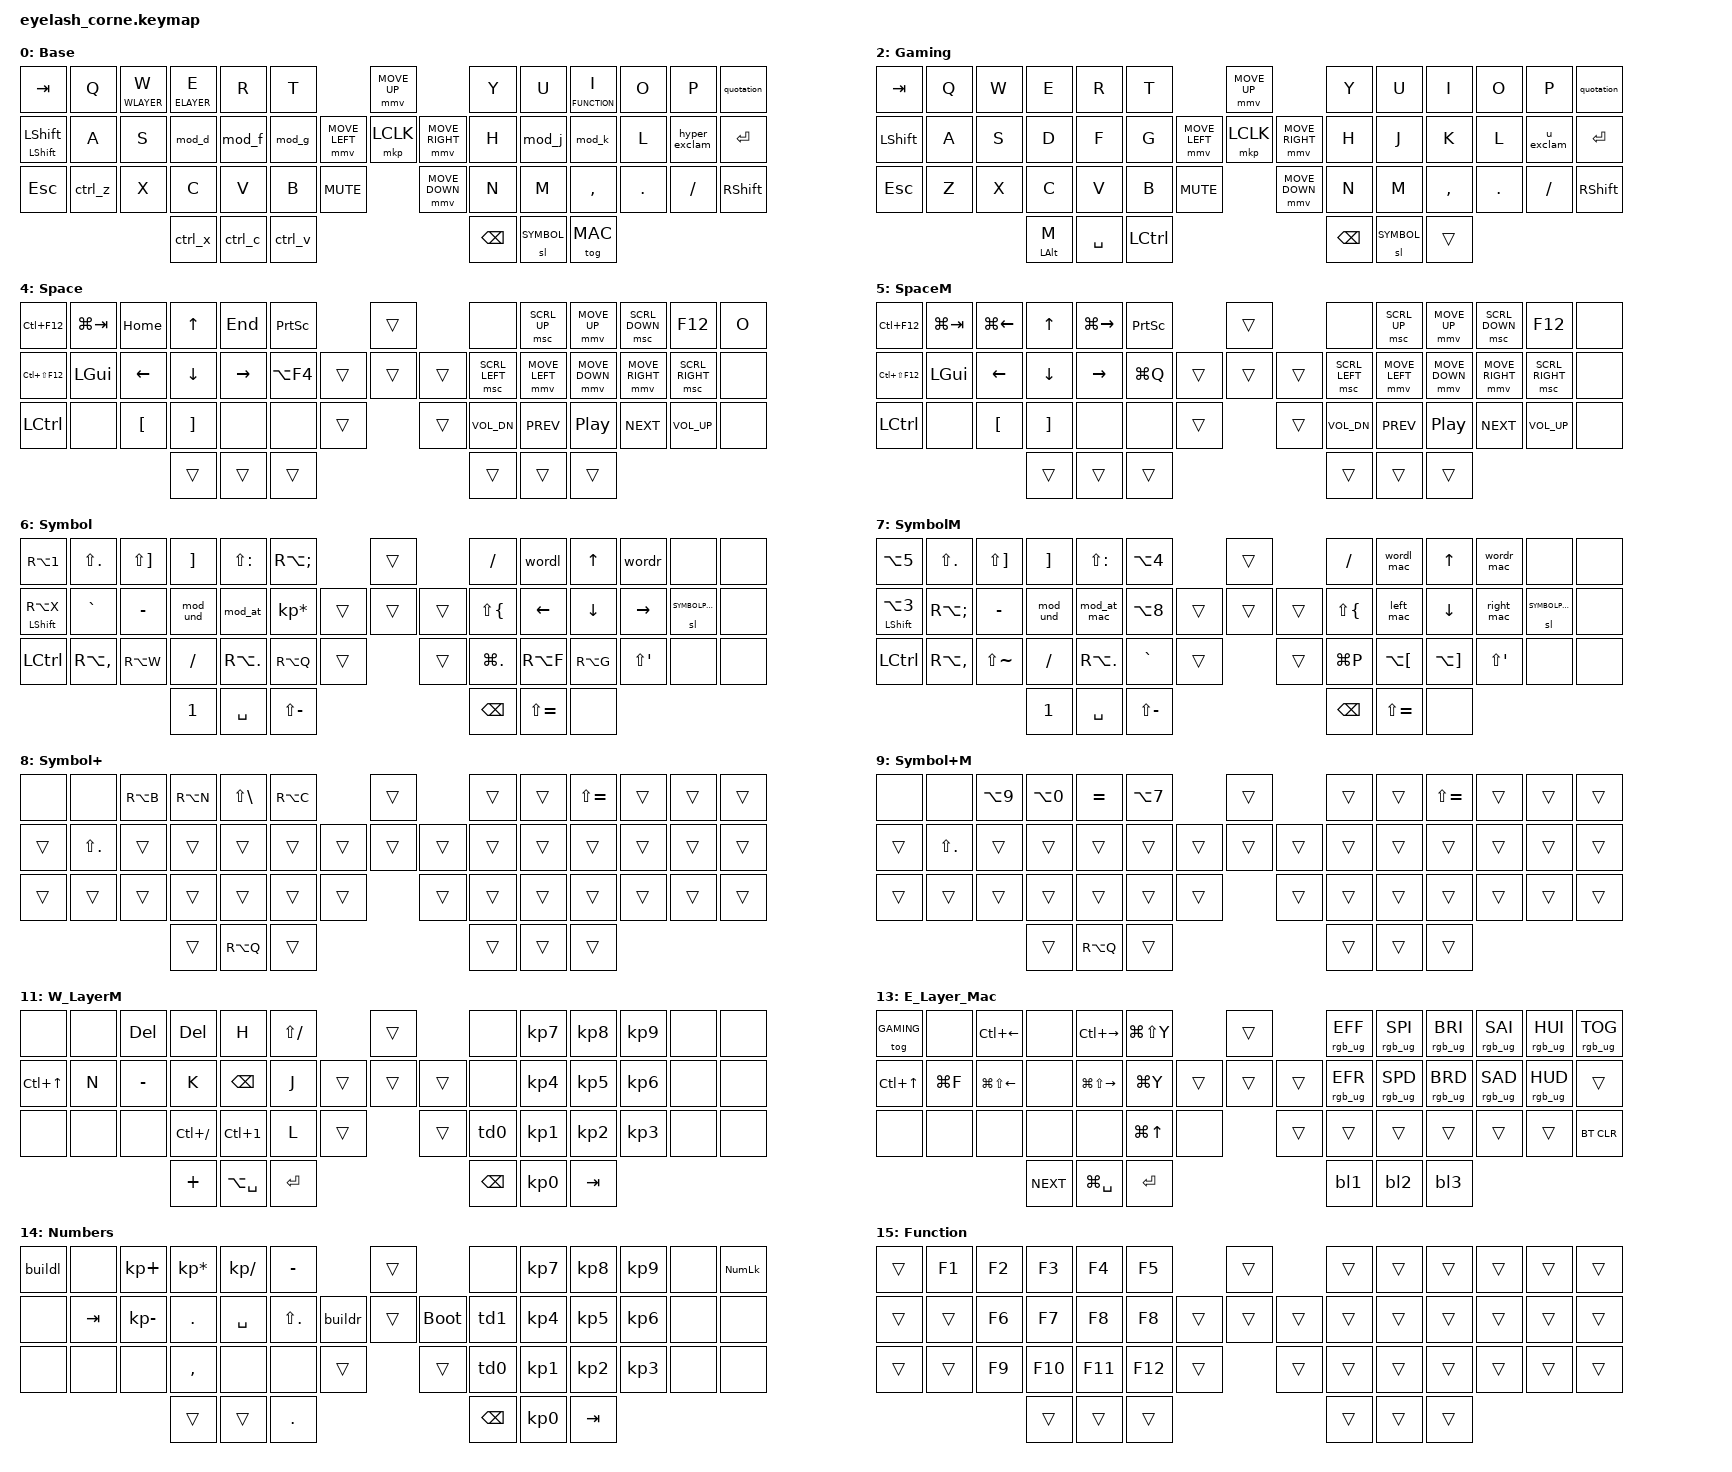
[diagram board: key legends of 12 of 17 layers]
#define ZMK_POINTING_DEFAULT_MOVE_VAL 1200  // 600
#define ZMK_POINTING_DEFAULT_SCRL_VAL 25   // 10

#include <input/processors.dtsi>
#include <zephyr/dt-bindings/input/input-event-codes.h>
#include <behaviors.dtsi>
#include <dt-bindings/zmk/bt.h>
#include <dt-bindings/zmk/keys.h>
#include <dt-bindings/zmk/outputs.h>
#include <dt-bindings/zmk/pointing.h>
#include <dt-bindings/zmk/rgb.h>

#define BASE 0
#define MAC 1
#define GAMING 2
#define GAMINGMAC 3
#define SPACELAYER 4
#define SPACELAYERMAC 5
#define SYMBOL 6
#define SYMBOLMAC 7
#define SYMBOLPLUS 8
#define SYMBOLPLUSMAC 9
#define WLAYER 10
#define WLAYERMAC 11
#define ELAYER 12
#define ELAYERMAC 13
#define NUMBERS 14
#define FUNCTION 15

// -------------------------------------------------------------------------------------------------------------------------------------------------------------------------------------------------------------------------------------------------------------------------------------------------------------------

// Caps Word
&caps_word {
    continue-list = <UNDERSCORE MINUS LS(SLASH) BACKSPACE>;
};

// Layer Tap
&lt {
    quick-tap-ms = <200>;
    tapping-term-ms = <200>;
};

// Sticky key
&sk {
    release-after-ms = <2000>;
    quick-release;
    /delete-property/ ignore-modifiers;
};

// Mouse Movement
&mmv {
    x-input-code = <INPUT_REL_X>;
    y-input-code = <INPUT_REL_Y>;
    time-to-max-speed-ms = <200>;
    acceleration-exponent = <1>;
};

// Mouse Scroll
&msc {
    x-input-code = <INPUT_REL_HWHEEL>;
    y-input-code = <INPUT_REL_WHEEL>;
    time-to-max-speed-ms = <1000>;
    acceleration-exponent = <2>;
};

// -------------------------------------------------------------------------------------------------------------------------------------------------------------------------------------------------------------------------------------------------------------------------------------------------------------------

//tab 0,    q 1,    w 2,   e 3,    r 4,    t 5,    y 7,    u 8,    i 9,    o 10,    p 11,   ' 12
//shift 13, a 14,   s 15,  d 16,   f 17,   g 18,   h 22,   j 23,   k 24,   l 25,   ; 26,   enter 27
//esc 28,   z 29,   x 30,  c 31,   v 32,   b 33,   n 36,   m 37,   , 38,   . 39,   / 40,   shift 40
//                                 42 43 44,           45 46 47

/ {
    combos {
        compatible = "zmk,combos";
        combo_rename {
            timeout-ms = <50>;
            key-positions = <1 2>;
            bindings = <&kp F2>;
        };

        combo_f5 {
            timeout-ms = <50>;
            key-positions = <3 15 17>;
            bindings = <&kp F5>;
            layers = <0 1 3 4 5 6>;  
        };

        combo_we {
            timeout-ms = <30>;
            key-positions = <2 3>;
            bindings = <&kp ESC>;
            layers = <0 1>; 
        };

        combo_lock {
            timeout-ms = <50>;
            key-positions = <11 12>;
            bindings = <&kp LG(L)>;
            layers = <0>; 
        };

        combo_lock_mac {
            timeout-ms = <50>;
            key-positions = <11 12>;
            bindings = <&kp LG(BSLH)>;
            layers = <1>; 
        }; 

        combo_sound {
            timeout-ms = <10>;
            key-positions = <14 18>;
            bindings = <&kp LG(A)>;
        };

        combo_m {
            timeout-ms = <10>;
            key-positions = <3 4>;
            bindings = <&kp M>;
            layers = <0 1>;  
        };

       combo_win_e {
            timeout-ms = <30>;
            key-positions = <3 44>;
            bindings = <&kp LG(E)>;
            layers = <0>;  
        };

       combo_finder {
            timeout-ms = <30>;
            key-positions = <3 44>;
            bindings = <&kp LA(LG(SPACE))>;
            layers = <1>;  
        };

       combo_gaming {
            timeout-ms = <30>;
            key-positions = <0 1>;
            bindings = <&tog GAMING>;
            layers = <0 1 2>;  
        };

       combo_mac {
            timeout-ms = <30>;
            key-positions = <0 13>;
            bindings = <&tog MAC>;
            layers = <0 1 2>;  
        };

    };
};

// -------------------------------------------------------------------------------------------------------------------------------------------------------------------------------------------------------------------------------------------------------------------------------------------------------------------

/ {
    macros {
        m_speed1: m_speed1 {
            compatible = "zmk,behavior-macro";
            #binding-cells = <0>;
            wait-ms = <200>;
            tap-ms = <20>;
            bindings
                = <&macro_tap &kp LS(R)>
                ,<&macro_wait_time 20>
                ,<&macro_tap &kp KP_N2 &kp KP_N0 &kp KP_N0>
                ,<&macro_wait_time 20>
                ,<&macro_tap &kp ENTER>
                ,<&macro_wait_time 20>
                ,<&macro_tap &kp LS(LC(LA(O)))>
                ,<&macro_tap &kp LS(LC(LA(O)))>
                ,<&macro_tap &kp LS(LC(LA(O)))>
                ,<&macro_tap &kp LS(LC(LA(O)))>
                ,<&macro_tap &kp LS(LC(LA(O)))>
                ,<&macro_tap &kp LS(LC(LA(O)))>
                ,<&macro_tap &kp LS(LC(LA(O)))>
                ,<&macro_tap &kp LS(LC(LA(O)))>
                ,<&macro_tap &kp LS(LC(LA(O)))>
                ,<&macro_tap &kp LS(LC(LA(O)))>
                ,<&macro_tap &kp LS(LC(LA(O)))>
                ;
        };
            m_speed2: m_speed2 {
            compatible = "zmk,behavior-macro";
            #binding-cells = <0>;
            wait-ms = <200>;
            tap-ms = <20>;
            bindings
                = <&macro_tap &kp LS(R)>
                ,<&macro_wait_time 20>
                ,<&macro_tap &kp KP_N4 &kp KP_N0 &kp KP_N0>
                ,<&macro_wait_time 20>
                ,<&macro_tap &kp ENTER>
                ,<&macro_wait_time 20>
                ,<&macro_tap &kp LS(LC(LA(O)))>
                ,<&macro_tap &kp LS(LC(LA(O)))>
                ,<&macro_tap &kp LS(LC(LA(O)))>
                ,<&macro_tap &kp LS(LC(LA(O)))>
                ,<&macro_tap &kp LS(LC(LA(O)))>
                ,<&macro_tap &kp LS(LC(LA(O)))>
                ,<&macro_tap &kp LS(LC(LA(O)))>
                ,<&macro_tap &kp LS(LC(LA(O)))>
                ,<&macro_tap &kp LS(LC(LA(O)))>
                ,<&macro_tap &kp LS(LC(LA(O)))>
                ,<&macro_tap &kp LS(LC(LA(O)))>
                ;
        };
            m_speed3: m_speed3 {
            compatible = "zmk,behavior-macro";
            #binding-cells = <0>;
            wait-ms = <200>;
            tap-ms = <20>;
            bindings
                = <&macro_tap &kp LS(R)>
                ,<&macro_wait_time 20>
                ,<&macro_tap &kp KP_N8 &kp KP_N0 &kp KP_N0>
                ,<&macro_wait_time 20>
                ,<&macro_tap &kp ENTER>
                ,<&macro_wait_time 20>
                ,<&macro_tap &kp LS(LC(LA(O)))>
                ,<&macro_tap &kp LS(LC(LA(O)))>
                ,<&macro_tap &kp LS(LC(LA(O)))>
                ,<&macro_tap &kp LS(LC(LA(O)))>
                ,<&macro_tap &kp LS(LC(LA(O)))>
                ,<&macro_tap &kp LS(LC(LA(O)))>
                ,<&macro_tap &kp LS(LC(LA(O)))>
                ,<&macro_tap &kp LS(LC(LA(O)))>
                ,<&macro_tap &kp LS(LC(LA(O)))>
                ,<&macro_tap &kp LS(LC(LA(O)))>
                ,<&macro_tap &kp LS(LC(LA(O)))>
                ;
        };
            m_del5: m_del5 {
            compatible = "zmk,behavior-macro";
            #binding-cells = <0>;
            wait-ms = <20>;
            tap-ms = <20>;
            bindings
                = 
                <&macro_tap &kp LS(LC(LA(L)))>
                ,<&macro_tap &kp RIGHT>
                ,<&macro_tap &kp RIGHT>
                ,<&macro_tap &kp RIGHT>
                ,<&macro_tap &kp RIGHT>
                ,<&macro_tap &kp RIGHT>
                ,<&macro_tap &kp Q>
                ,<&macro_tap &kp LEFT>
                ,<&macro_tap &kp LEFT>
                ,<&macro_tap &kp LEFT>
                ,<&macro_tap &kp LEFT>
                ,<&macro_tap &kp LEFT>
                ,<&macro_tap &kp LEFT>
                ,<&macro_tap &kp LEFT>
                ,<&macro_tap &kp LEFT>
                ,<&macro_tap &kp LEFT>
                ,<&macro_tap &kp LEFT>
                ,<&macro_tap &kp LEFT>
                ,<&macro_tap &kp LEFT>
                ,<&macro_tap &kp LEFT>
                ,<&macro_tap &kp LEFT>
                ,<&macro_tap &kp LEFT>
                ,<&macro_tap &kp LEFT>
                ,<&macro_tap &kp SPACE>
                ;
        };
            m_mute: m_mute {
            compatible = "zmk,behavior-macro";
            #binding-cells = <0>;
            wait-ms = <20>;
            tap-ms = <20>;
            bindings
                = 
                <&macro_tap &kp LS(LC(LA(O)))>
                ,<&macro_tap &kp LS(LC(LA(O)))>
                ,<&macro_tap &kp LS(LC(LA(O)))>
                ,<&macro_tap &kp LS(LC(LA(O)))>
                ,<&macro_tap &kp LS(LC(LA(O)))>
                ,<&macro_tap &kp LS(LC(LA(O)))>
                ,<&macro_tap &kp LS(LC(LA(O)))>
                ,<&macro_tap &kp LS(LC(LA(O)))>
                ,<&macro_tap &kp LS(LC(LA(O)))>
                ,<&macro_tap &kp LS(LC(LA(O)))>
                ,<&macro_tap &kp LS(LC(LA(O)))>
                ;
        };
            caret: caret {
            compatible = "zmk,behavior-macro";
            #binding-cells = <0>;
            wait-ms = <1>;
            tap-ms = <1>;
            bindings
            = <&macro_press &kp LALT>
            , <&macro_tap &kp KP_N9 &kp KP_N4>
            , <&macro_release &kp LALT>
            ;

        };

            backtick: backtick {
            compatible = "zmk,behavior-macro";
            #binding-cells = <0>;
            wait-ms = <1>;
            tap-ms = <1>;
            bindings
            = <&macro_press &kp LALT>
            , <&macro_tap &kp KP_N0 &kp KP_N9 &kp KP_N6>
            , <&macro_release &kp LALT>
            ;

        };

            buildl: buildl {
            compatible = "zmk,behavior-macro";
            #binding-cells = <0>;
            wait-ms = <40>;
            tap-ms = <40>;
            bindings
            = <&macro_tap &kp LS(LC(LA(UP)))>
            , <&macro_tap &bootloader>
            ;

        };

            buildr: buildr {
            compatible = "zmk,behavior-macro";
            #binding-cells = <0>;
            wait-ms = <100>;
            tap-ms = <100>;
            bindings
            = <&macro_tap &kp LS(LC(LA(DOWN)))>
            ;

        };
            cstest: cstest {
            compatible = "zmk,behavior-macro";
            #binding-cells = <0>;
            wait-ms = <40>;
            tap-ms = <40>;
            bindings
                = 
                <&macro_tap &kp N1>
                ,<&macro_tap &kp DOT &kp B &kp K &kp K &kp ENTER>
                ,<&macro_tap &kp DOT &kp F &kp T &kp M &kp ENTER>
                ,<&macro_tap &kp DOT &kp M &kp P &kp I &kp ENTER>
                 ;
        };

            swapp: swapp {
            compatible = "zmk,behavior-macro";
            #binding-cells = <0>;
            wait-ms = <1>;
            tap-ms = <1>;
            bindings
                = 
                <&macro_press &kp LALT>
                ,<&macro_tap &kp TAB>
                ,<&macro_release &kp LALT>
                 ;
        };

            bl1: bluetooth_layer_1 {
            compatible = "zmk,behavior-macro";
            #binding-cells = <0>;
            wait-ms = <20>;
            tap-ms = <20>;
            bindings
                = <&macro_tap &bt BT_SEL 0>
                , <&macro_tap &to BASE>
                 ;
        };

            bl2: bluetooth_layer_2 {
            compatible = "zmk,behavior-macro";
            #binding-cells = <0>;
            wait-ms = <20>;
            tap-ms = <20>;
            bindings
                = <&macro_tap &bt BT_SEL 1>
                , <&macro_tap &to MAC>
                 ;
        };

            bl3: bluetooth_layer_3 {
            compatible = "zmk,behavior-macro";
            #binding-cells = <0>;
            wait-ms = <20>;
            tap-ms = <20>;
            bindings
                = <&macro_tap &bt BT_SEL 2>
                , <&macro_tap &to MAC>
                 ;
        };
    };
};

// -------------------------------------------------------------------------------------------------------------------------------------------------------------------------------------------------------------------------------------------------------------------------------------------------------------------

&mmv_input_listener { input-processors = <&zip_xy_scaler 2 1>; };

&msc_input_listener { input-processors = <&zip_scroll_scaler 2 1>; };

&msc {
    acceleration-exponent = <1>;      // 0
    time-to-max-speed-ms = <100>;       // 300
    delay-ms = <0>;                   // 0
};

&mmv {
    time-to-max-speed-ms = <500>;
    acceleration-exponent = <1>;
    trigger-period-ms = <16>;
};

// -------------------------------------------------------------------------------------------------------------------------------------------------------------------------------------------------------------------------------------------------------------------------------------------------------------------

/ {
    rgb_encoder: rgb_encoder {
        compatible = "zmk,behavior-sensor-rotate";
        #sensor-binding-cells = <0>;
        bindings = <&rgb_ug RGB_BRI>, <&rgb_ug RGB_BRD>;
    };

    scroll_encoder: scroll_encoder {
        compatible = "zmk,behavior-sensor-rotate";
        #sensor-binding-cells = <0>;
        bindings = <&msc SCRL_DOWN>, <&msc SCRL_UP>;

        tap-ms = <100>;
    };

    behaviors {
        bhm: balanced_homerow_mods {
            compatible = "zmk,behavior-hold-tap";
            #binding-cells = <2>;
            tapping-term-ms = <150>;    // <---[[moderate duration]]
            quick-tap-ms = <200>;
            //require-prior-idle-ms = <125>;
            flavor = "balanced";
            bindings = <&kp>, <&kp>;
            hold-while-undecided;
        };
    };

    behaviors {
        thm: tap_homerow_mods {
            compatible = "zmk,behavior-hold-tap";
            #binding-cells = <2>;
            tapping-term-ms = <150>;    // <---[[moderate duration]]
            quick-tap-ms = <200>;
            //require-prior-idle-ms = <125>;
            flavor = "tap-preferred";
            bindings = <&kp>, <&kp>;
            hold-while-undecided;
        };
    };

    behaviors {
        ebhm: enhanced_balanced_homerow_mods {
            compatible = "zmk,behavior-hold-tap";
            #binding-cells = <2>;
            tapping-term-ms = <150>;    // <---[[moderate duration]]
            quick-tap-ms = <200>;
            //require-prior-idle-ms = <125>;
            flavor = "balanced";
            bindings = <&kp>, <&sl>;
            hold-while-undecided;
        };
    };

    behaviors {
        lkp: layer_keypress {
            compatible = "zmk,behavior-hold-tap";
            #binding-cells = <2>;
            tapping-term-ms = <200>;    // <---[[moderate duration]]
            quick-tap-ms = <200>;
            require-prior-idle-ms = <125>;
            flavor = "tap-preferred";
            bindings = <&mo>, <&kp>;
        };
    };

    behaviors {
        lshift: lshift_hold_tap {
            compatible = "zmk,behavior-hold-tap";
            #binding-cells = <2>;
            flavor = "balanced";
            tapping-term-ms = <400>;
            quick-tap-ms = <200>;
            bindings = <&kp>, <&sk>;
        };
    };
    
    behaviors {
        td0: tap_dance_0 {
            compatible = "zmk,behavior-tap-dance";
            #binding-cells = <0>;
            tapping-term-ms = <300>;
            bindings = <&kp KP_MULTIPLY>, <&kp KP_DIVIDE>;
        };
    };

    behaviors {
        td1: tap_dance_1 {
            compatible = "zmk,behavior-tap-dance";
            #binding-cells = <0>;
            tapping-term-ms = <300>;
            bindings = <&kp KP_MINUS>, <&kp KP_PLUS>; 
        };
    };

    behaviors {
        quotation: quotation {
            compatible = "zmk,behavior-mod-morph"; 
            #binding-cells = <0>;
            bindings = <&kp LS(BSLH)>, <&kp SEMI>;
            mods = <(MOD_LSFT|MOD_RSFT)>;
            keep-mods = <(MOD_LSFT)>;
        };
    };


    behaviors {
        wordl: wordl {
            compatible = "zmk,behavior-mod-morph"; 
            #binding-cells = <0>;
            bindings = <&kp HOME >, <&kp HOME>;
            mods = <(MOD_LCTL|MOD_RCTL)>;
        };
    };

    behaviors {
        wordr: wordr {
            compatible = "zmk,behavior-mod-morph"; 
            #binding-cells = <0>;
            bindings = <&kp END >, <&kp END>;
            mods = <(MOD_LCTL|MOD_RCTL)>;
        };
    };

    behaviors {
        wordl_mac: wordl_mac {
            compatible = "zmk,behavior-mod-morph"; 
            #binding-cells = <0>;
            bindings = <&kp LG(LEFT)>, <&kp LG(LEFT)>;
            mods = <(MOD_LGUI|MOD_RGUI)>;
        };
    };

    behaviors {
        wordr_mac: wordr_mac {
            compatible = "zmk,behavior-mod-morph"; 
            #binding-cells = <0>;
            bindings = <&kp LG(RIGHT)>, <&kp LG(RIGHT)>;
            mods = <(MOD_LGUI|MOD_RGUI)>;
        };
    };

    behaviors {
        left_mac: left_mac {
            compatible = "zmk,behavior-mod-morph"; 
            #binding-cells = <0>;
            bindings = <&kp LEFT >, <&kp LA(LEFT)>;
            mods = <(MOD_LGUI|MOD_RGUI)>;
        };
    };

    behaviors {
        right_mac: right_mac {
            compatible = "zmk,behavior-mod-morph"; 
            #binding-cells = <0>;
            bindings = <&kp RIGHT >, <&kp LA(RIGHT)>;
            mods = <(MOD_LGUI|MOD_RGUI)>;
        };
    };

    behaviors {
        bspc_hacek: backspace_hacek {
            compatible = "zmk,behavior-mod-morph";
            #binding-cells = <0>;
            bindings = <&kp ENTER>, <&kp EQUAL>;
            mods = <(MOD_LSFT|MOD_RSFT)>;
            keep-mods = <(MOD_LSFT)>;
        };
    };

    behaviors {
        u_exclam: u_exclam {
            compatible = "zmk,behavior-mod-morph";
            #binding-cells = <0>;
            bindings = <&kp SEMI>, <&kp SQT>;
            mods = <(MOD_LSFT|MOD_RSFT)>;
            keep-mods = <(MOD_LSFT)>;
        };
    };

    behaviors {
        hyper_exclam: hyper_exclam {
            compatible = "zmk,behavior-mod-morph";
            #binding-cells = <0>;
            bindings = <&bhm LS(LA(LG(LCTRL))) LS(BSLH)>, <&kp SQT>;
            mods = <(MOD_LSFT|MOD_RSFT)>;
            keep-mods = <(MOD_LSFT)>;
        };
    }; 

    behaviors {
        exclam_mac: exclam_mac {
            compatible = "zmk,behavior-mod-morph";
            #binding-cells = <0>;
            bindings = <&kp RA(SQT)>, <&kp SQT>;
            mods = <(MOD_LSFT|MOD_RSFT)>;
            keep-mods = <(MOD_LSFT)>;
        };
    };

    behaviors {
        ctrl_z: ctrl_z {
            compatible = "zmk,behavior-mod-morph";
            #binding-cells = <0>;
            bindings = <&kp Z>, <&kp Y>;
            mods = <(MOD_LCTL)>; 
            keep-mods = <(MOD_LCTL)>;
        };
    }; 

    behaviors {
        ctrl_c: ctrl_c {
            compatible = "zmk,behavior-mod-morph";
            #binding-cells = <0>;
            bindings = <&lkp SPACELAYER SPACE>, <&kp C>;
            mods = <(MOD_LCTL)>;
            keep-mods = <(MOD_LCTL)>;
        };
    };

    behaviors {
        ctrl_c_mac: ctrl_c_mac {
            compatible = "zmk,behavior-mod-morph";
            #binding-cells = <0>;
            bindings = <&lkp SPACELAYERMAC SPACE>, <&kp C>;
            mods = <(MOD_LGUI)>;
            keep-mods = <(MOD_LGUI)>;
        };
    };

    behaviors {
        bspc_del: bspc_del {
            compatible = "zmk,behavior-mod-morph";
            #binding-cells = <0>;
            bindings = <&kp BACKSPACE>, <&kp DEL>;
            mods = <(MOD_LSFT)>;
        };
    };

    //Ctrl V
    behaviors {
        ctrl_v: ctrl_v {
            compatible = "zmk,behavior-mod-morph";
            #binding-cells = <0>;
            bindings = <&bhm LALT ESC>, <&kp V>;
            mods = <(MOD_LCTL)>;
            keep-mods = <(MOD_LCTL)>;
        };
    };
    
      behaviors {
        ctrl_v_mac: ctrl_v_mac {
            compatible = "zmk,behavior-mod-morph";
            #binding-cells = <0>;
            bindings = <&bhm LALT ESC>, <&kp V>;
            mods = <(MOD_LGUI)>;
            keep-mods = <(MOD_LGUI)>;
        };
    };

    behaviors {
            ctrl_x: ctrl_x {
                compatible = "zmk,behavior-mod-morph";
                #binding-cells = <0>;
                bindings = <&sl NUMBERS>, <&kp X>;
                mods = <(MOD_LCTL)>;
                keep-mods = <(MOD_LCTL)>;
            };
        };

    behaviors {
            ctrl_x_mac: ctrl_x_mac {
                compatible = "zmk,behavior-mod-morph";
                #binding-cells = <0>;
                bindings = <&sl NUMBERS>, <&kp X>;
                mods = <(MOD_LGUI)>;
                keep-mods = <(MOD_LGUI)>;
            };
        };

    behaviors {
            mod_f: mod_f {
                compatible = "zmk,behavior-mod-morph";
                #binding-cells = <0>;
                bindings = <&bhm LCTL F>, <&kp F>;
                mods = <(MOD_LSFT)>;
                keep-mods = <(MOD_LSFT)>;
            };
        };

    behaviors {
            mod_f_mac: mod_f_mac {
                compatible = "zmk,behavior-mod-morph";
                #binding-cells = <0>;
                bindings = <&bhm LGUI F>, <&kp F>;
                mods = <(MOD_LSFT)>;
                keep-mods = <(MOD_LSFT)>;
            };
        };
        
    behaviors {
            mod_g: mod_g {
                compatible = "zmk,behavior-mod-morph";
                #binding-cells = <0>;
                bindings = <&bhm LC(LS(LALT)) G>, <&kp G>;
                mods = <(MOD_LGUI|MOD_LSFT|MOD_RGUI|MOD_RSFT|MOD_LCTL)>;
                keep-mods = <(MOD_LGUI|MOD_LSFT|MOD_RGUI|MOD_RSFT|MOD_LCTL)>;
            };
        };

    behaviors {
            mod_t: mod_t {
                compatible = "zmk,behavior-mod-morph";
                #binding-cells = <0>;
                bindings = <&bhm LG(LC(LS(LALT))) T>, <&kp T>;
                mods = <(MOD_LGUI|MOD_LSFT|MOD_RGUI|MOD_RSFT|MOD_LCTL)>;
                keep-mods = <(MOD_LGUI|MOD_LSFT|MOD_RGUI|MOD_RSFT|MOD_LCTL)>;
            };
        };

    behaviors {
            mod_d: mod_d {
                compatible = "zmk,behavior-mod-morph";
                #binding-cells = <0>;
                bindings = <&bhm LSHFT D>, <&kp D>;
                mods = <(MOD_LSFT)>;
                keep-mods = <(MOD_LSFT)>;
            };
        };

    behaviors {
            mod_j: mod_j {
                compatible = "zmk,behavior-mod-morph";
                #binding-cells = <0>;
                bindings = <&bhm LCTL J>, <&kp J>;
                mods = <(MOD_LSFT)>;
                keep-mods = <(MOD_LSFT)>;
            };
        };

    behaviors {
            mod_j_mac: mod_j_mac {
                compatible = "zmk,behavior-mod-morph";
                #binding-cells = <0>;
                bindings = <&bhm LGUI J>, <&kp J>;
                mods = <(MOD_LSFT)>;
                keep-mods = <(MOD_LSFT)>;
            };
        };

    behaviors {
            mod_k: mod_k {
                compatible = "zmk,behavior-mod-morph";
                #binding-cells = <0>;
                bindings = <&bhm LSHFT K>, <&kp K>;
                mods = <(MOD_LSFT)>;
                keep-mods = <(MOD_LSFT)>;
            };
        };
        
    behaviors {
            mod_at: mod_at {
                compatible = "zmk,behavior-mod-morph";
                #binding-cells = <0>;
                bindings = <&bhm LCTL RA(V)>, <&kp RA(V)>;
                mods = <(MOD_LSFT)>;
                keep-mods = <(MOD_LSFT)>;
            };
        };

    behaviors {
            mod_at_mac: mod_at_mac {
                compatible = "zmk,behavior-mod-morph";
                #binding-cells = <0>;
                bindings = <&bhm LGUI LA(N2)>, <&kp LA(N2)>;
                mods = <(MOD_LSFT)>;
                keep-mods = <(MOD_LSFT)>;
            };
        };

    behaviors {
            mod_und: mod_und {
                compatible = "zmk,behavior-mod-morph";
                #binding-cells = <0>;
                bindings = <&bhm LSFT LS(SLASH)>, <&kp LS(SLASH)>;
                mods = <(MOD_LSFT)>;
                keep-mods = <(MOD_LSFT)>;
            };
        };


// -------------------------------------------------------------------------------------------------------------------------------------------------------------------------------------------------------------------------------------------------------------------------------------------------------------------
    keymap {
        compatible = "zmk,keymap";

        default_layer {
            display-name = "Base";
            bindings = <
&kp TAB               &kp Q          &lt WLAYER W   &lt ELAYER E     &kp R          &kp T                                         &mmv MOVE_UP                      &kp Y             &kp U             &lt FUNCTION I  &kp O           &kp P            &quotation
&lshift LSHFT LSHFT   &kp A          &kp S          &mod_d           &mod_f         &mod_g                        &mmv MOVE_LEFT  &mkp LCLK &mmv MOVE_RIGHT         &kp H             &mod_j            &mod_k          &kp L           &hyper_exclam    &kp ENTER
&kp ESC               &ctrl_z        &kp X          &kp C            &kp V          &kp B          &kp C_MUTE                     &mmv MOVE_DOWN                    &kp N             &kp M             &kp COMMA       &kp DOT         &kp FSLH         &kp RSHFT
                                                    &ctrl_x          &ctrl_c        &ctrl_v                                                                         &kp BSPC          &sl SYMBOL        &tog MAC  
            >;

             sensor-bindings = <&scroll_encoder>;
        };
// -------------------------------------------------------------------------------------------------------------------------------------------------------------------------------------------------------------------------------------------------------------------------------------------------------------------
        base_mac {
            display-name = "Mac";
            bindings = <
&trans              &trans              &lt WLAYERMAC W     &lt ELAYERMAC E     &trans              &trans                                            &trans                       &trans              &trans              &lt FUNCTION I      &trans              &trans                  &quotation      
&trans              &trans              &trans              &trans              &mod_f_mac          &trans                            &trans          &trans     &trans            &trans              &mod_j_mac          &trans              &trans              &exclam_mac             &kp ENTER
&trans              &trans              &trans              &trans              &trans              &trans              &trans                        &trans                       &trans              &trans              &trans              &trans              &trans                  &trans    
                                                            &ctrl_x_mac         &ctrl_c_mac         &ctrl_v_mac                                                                    &kp BSPC            &sl SYMBOLMAC       &kp LS(LA(LG(LCTRL)))
            >;

            sensor-bindings = <&scroll_encoder>;
        };
// -------------------------------------------------------------------------------------------------------------------------------------------------------------------------------------------------------------------------------------------------------------------------------------------------------------------
        lower_layer {
            display-name = "Gaming";
            bindings = <
&kp TAB           &kp Q           &kp W           &kp E           &kp R           &kp T                                            &mmv MOVE_UP                      &kp Y           &kp U           &kp I           &kp O           &kp P           &quotation
&kp LSHFT         &kp A           &kp S           &kp D           &kp F           &kp G                            &mmv MOVE_LEFT  &mkp LCLK &mmv MOVE_RIGHT         &kp H           &kp J           &kp K           &kp L           &u_exclam       &kp ENTER
&kp ESC           &kp Z           &kp X           &kp C           &kp V           &kp B           &kp C_MUTE                       &mmv MOVE_DOWN                    &kp N           &kp M           &kp COMMA       &kp DOT         &kp FSLH        &kp RSHFT
                                                  &bhm LALT M     &kp SPACE       &kp LCTRL                                                                          &kp BSPC        &sl SYMBOL       &trans    
            >;

            sensor-bindings = <&scroll_encoder>;
        };
// -------------------------------------------------------------------------------------------------------------------------------------------------------------------------------------------------------------------------------------------------------------------------------------------------------------------
        gaming_mac {
            display-name = "GamingM";
            bindings = <
&kp TAB           &kp Q           &kp W           &kp E           &kp R           &kp T                                            &mmv MOVE_UP                      &kp Y           &kp U           &kp I           &kp O           &kp P           &quotation
&kp LSHFT         &kp A           &kp S           &kp D           &kp F           &kp G                            &mmv MOVE_LEFT  &mkp LCLK &mmv MOVE_RIGHT         &kp H           &kp J           &kp K           &kp L           &u_exclam       &bhm LS(LA(LG(LCTRL))) ENTER 
&kp ESC           &kp Z           &kp X           &kp C           &kp V           &kp B           &kp C_MUTE                       &mmv MOVE_DOWN                    &kp N           &kp M           &kp COMMA       &kp DOT         &kp FSLH        &kp RSHFT
                                                  &kp LALT        &kp SPACE       &kp LCTRL                                                                          &kp BSPC        &sl SYMBOLMAC   &trans    
            >;

            sensor-bindings = <&scroll_encoder>;
        };
// -------------------------------------------------------------------------------------------------------------------------------------------------------------------------------------------------------------------------------------------------------------------------------------------------------------------
        space_layer {
            display-name = "Space";
            bindings = <
&kp LC(F12)         &kp LG(TAB)        &kp HOME             &kp UP              &kp END             &kp PSCRN                                         &trans                       &none               &msc SCRL_UP        &mmv MOVE_UP        &msc SCRL_DOWN      &kp F12             &kp O
&kp LC(LS(F12))     &kp LGUI           &kp LEFT             &kp DOWN            &kp RIGHT           &kp LA(F4)                        &trans          &trans     &trans            &msc SCRL_LEFT      &mmv MOVE_LEFT      &mmv MOVE_DOWN      &mmv MOVE_RIGHT     &msc SCRL_RIGHT     &none
&kp LCTL            &none              &kp LBKT             &kp RBKT            &none               &none               &trans                        &trans                       &kp C_VOL_DN        &kp C_PREV          &kp C_PP            &kp C_NEXT          &kp C_VOL_UP        &none
                                                            &trans              &trans              &trans                                                                         &trans              &trans              &trans   
            >;

            sensor-bindings = <&scroll_encoder>;
        };
// -------------------------------------------------------------------------------------------------------------------------------------------------------------------------------------------------------------------------------------------------------------------------------------------------------------------
        space_layer_mac {
            display-name = "SpaceM";
            bindings = <
&kp LC(F12)         &kp LG(TAB)        &kp LG(LEFT)         &kp UP              &kp LG(RIGHT)      &kp PSCRN                                         &trans                       &none               &msc SCRL_UP        &mmv MOVE_UP        &msc SCRL_DOWN      &kp F12             &none
&kp LC(LS(F12))     &kp LGUI           &kp LEFT             &kp DOWN            &kp RIGHT           &kp LG(Q)                         &trans          &trans     &trans            &msc SCRL_LEFT      &mmv MOVE_LEFT      &mmv MOVE_DOWN      &mmv MOVE_RIGHT     &msc SCRL_RIGHT     &none
&kp LCTL            &none              &kp LBKT             &kp RBKT            &none               &none               &trans                        &trans                       &kp C_VOL_DN        &kp C_PREV          &kp C_PP            &kp C_NEXT          &kp C_VOL_UP        &none
                                                            &trans              &trans              &trans                                                                         &trans              &trans              &trans   
            >;

            sensor-bindings = <&scroll_encoder>;
        };
// -------------------------------------------------------------------------------------------------------------------------------------------------------------------------------------------------------------------------------------------------------------------------------------------------------------------
        symbol {
            display-name = "Symbol";
            bindings = <
&kp RA(N1)          &kp LS(DOT)         &kp LS(RBKT)        &kp RBKT            &kp LS(COLON)       &kp RA(SEMI)                                      &trans                       &kp FSLH            &wordl              &kp UP              &wordr              &none              &none
&bhm LSHFT RA(X)    &kp GRAVE           &kp MINUS           &mod_und            &mod_at             &kp KP_MULTIPLY                   &trans          &trans     &trans            &kp LS(LBRC)        &kp LEFT            &kp DOWN            &kp RIGHT           &sl SYMBOLPLUS     &none  
&kp LCTL            &kp RA(COMMA)       &kp RA(W)           &kp FSLH            &kp RA(DOT)         &kp RA(Q)           &trans                        &trans                       &kp LG(DOT)         &kp RA(F)           &kp RA(G)           &kp LS(SQT)         &none              &none  
                                                            &kp N1              &kp SPACE           &kp LS(MINUS)                                                                  &kp BACKSPACE       &kp LS(EQUAL)       &none
            >;

            sensor-bindings = <&scroll_encoder>;
        };
// -------------------------------------------------------------------------------------------------------------------------------------------------------------------------------------------------------------------------------------------------------------------------------------------------------------------
        symbol_mac {
            display-name = "SymbolM";
            bindings = <
&kp LA(N5)          &kp LS(DOT)         &kp LS(RBKT)        &kp RBKT            &kp LS(COLON)       &kp LA(N4)                                        &trans                       &kp FSLH            &wordl_mac          &kp UP              &wordr_mac          &none              &none
&bhm LSHFT LA(N3)   &kp RA(SEMI)        &kp MINUS           &mod_und            &mod_at_mac         &kp LA(N8)                        &trans          &trans     &trans            &kp LS(LBRC)        &left_mac           &kp DOWN            &right_mac          &sl SYMBOLPLUSMAC  &none  
&kp LCTL            &kp RA(COMMA)       &kp LS(TILDE)       &kp FSLH            &kp RA(DOT)         &kp GRAVE           &trans                        &trans                       &kp LG(P)           &kp LA(LBKT)        &kp LA(RBKT)        &kp LS(SQT)         &none              &none  
                                                            &kp N1              &kp SPACE           &kp LS(MINUS)                                                                  &kp BACKSPACE       &kp LS(EQUAL)       &none   
            >;

            sensor-bindings = <&scroll_encoder>;
        };
// -------------------------------------------------------------------------------------------------------------------------------------------------------------------------------------------------------------------------------------------------------------------------------------------------------------------
        symbol_plus {
            display-name = "Symbol+";
            bindings = <
&none               &none               &kp RA(B)           &kp RA(N)           &kp LS(BSLH)        &kp RA(C)                                         &trans                       &trans              &trans              &kp LS(EQUAL)       &trans              &trans              &trans      
&trans              &kp LS(DOT)         &trans              &trans              &trans              &trans                            &trans          &trans     &trans            &trans              &trans              &trans              &trans              &trans              &trans    
&trans              &trans              &trans              &trans              &trans              &trans              &trans                        &trans                       &trans              &trans              &trans              &trans              &trans              &trans    
                                                            &trans              &kp RA(Q)           &trans                                                                         &trans              &trans              &trans     
            >;

            sensor-bindings = <&scroll_encoder>;
        };
// -------------------------------------------------------------------------------------------------------------------------------------------------------------------------------------------------------------------------------------------------------------------------------------------------------------------
        symbol_plus_mac {
            display-name = "Symbol+M";
            bindings = <
&none               &none               &kp LA(N9)          &kp LA(N0)          &kp EQUAL           &kp LA(N7)                                        &trans                       &trans              &trans              &kp LS(EQUAL)       &trans              &trans              &trans      
&trans              &kp LS(DOT)         &trans              &trans              &trans              &trans                            &trans          &trans     &trans            &trans              &trans              &trans              &trans              &trans              &trans    
&trans              &trans              &trans              &trans              &trans              &trans              &trans                        &trans                       &trans              &trans              &trans              &trans              &trans              &trans    
                                                            &trans              &kp RA(Q)           &trans                                                                         &trans              &trans              &trans     
            >;

            sensor-bindings = <&scroll_encoder>;
        };
// -------------------------------------------------------------------------------------------------------------------------------------------------------------------------------------------------------------------------------------------------------------------------------------------------------------------
        w_layer {
            display-name = "W_Layer";
            bindings = <  
&none               &none               &kp DEL             &kp DEL             &kp H               &kp LS(SLASH)                                     &trans                       &none               &kp KP_N7           &kp KP_N8           &kp KP_N9           &none               &none
&kp LG(TAB)         &kp N               &kp MINUS           &kp K               &kp BSPC            &kp J                             &trans          &trans     &trans            &none               &kp KP_N4           &kp KP_N5           &kp KP_N6           &none               &none  
&none               &none               &none               &kp LC(FSLH)        &kp LC(N1)          &kp L               &trans                        &trans                       &td0                &kp KP_N1           &kp KP_N2           &kp KP_N3           &none               &none
                                                            &kp PLUS            &kp LS(LC(LA(N)))   &kp ENTER                                                                      &kp BSPC            &kp KP_N0           &kp TAB   
            >;

            sensor-bindings = <&scroll_encoder>;
        };
// -------------------------------------------------------------------------------------------------------------------------------------------------------------------------------------------------------------------------------------------------------------------------------------------------------------------
        w_layer_mac {
            display-name = "W_LayerM";
            bindings = <  
&none               &none               &kp DEL             &kp DEL             &kp H               &kp LS(SLASH)                                     &trans                       &none               &kp KP_N7           &kp KP_N8           &kp KP_N9           &none               &none
&kp LC(UP)          &kp N               &kp MINUS           &kp K               &kp BSPC            &kp J                             &trans          &trans     &trans            &none               &kp KP_N4           &kp KP_N5           &kp KP_N6           &none               &none  
&none               &none               &none               &kp LC(FSLH)        &kp LC(N1)          &kp L               &trans                        &trans                       &td0                &kp KP_N1           &kp KP_N2           &kp KP_N3           &none               &none
                                                            &kp PLUS            &kp LA(SPACE)       &kp ENTER                                                                      &kp BSPC            &kp KP_N0           &kp TAB   
            >;

            sensor-bindings = <&scroll_encoder>;
        };
// -------------------------------------------------------------------------------------------------------------------------------------------------------------------------------------------------------------------------------------------------------------------------------------------------------------------
        e_layer {
            display-name = "E_Layer";
            bindings = <  
&tog GAMING         &none               &kp LC(LG(LEFT))    &none               &kp LC(LG(RIGHT))   &kp LC(Z)                                            &trans                       &rgb_ug RGB_EFF       &rgb_ug RGB_SPI     &rgb_ug RGB_BRI     &rgb_ug RGB_SAI     &rgb_ug RGB_HUI     &rgb_ug RGB_TOG      
&kp LG(TAB)         &kp LC(F)           &kp LG(LS(LEFT))    &none               &kp LG(LS(RIGHT))   &kp LC(Y)                            &trans          &trans     &trans            &rgb_ug RGB_EFR       &rgb_ug RGB_SPD     &rgb_ug RGB_BRD     &rgb_ug RGB_SAD     &rgb_ug RGB_HUD     &trans    
&none               &none               &none               &none               &none               &kp LG(UP)           &none                           &trans                       &trans                &trans              &trans              &trans              &trans              &bt BT_CLR       
                                                            &kp C_NEXT          &kp LS(LC(LA(DOT))) &kp ENTER                                                                         &bl1                  &bl2                &bl3
            >;

            sensor-bindings = <&scroll_encoder>;
        };
// -------------------------------------------------------------------------------------------------------------------------------------------------------------------------------------------------------------------------------------------------------------------------------------------------------------------
        e_layer_mac {
            display-name = "E_Layer_Mac";
            bindings = <  
&tog GAMING         &none               &kp LC(LEFT)        &none               &kp LC(RIGHT)       &kp LG(LS(Y))                                        &trans                       &rgb_ug RGB_EFF       &rgb_ug RGB_SPI     &rgb_ug RGB_BRI     &rgb_ug RGB_SAI     &rgb_ug RGB_HUI     &rgb_ug RGB_TOG      
&kp LC(UP)          &kp LG(F)           &kp LG(LS(LEFT))    &none               &kp LG(LS(RIGHT))   &kp LG(Y)                            &trans          &trans     &trans            &rgb_ug RGB_EFR       &rgb_ug RGB_SPD     &rgb_ug RGB_BRD     &rgb_ug RGB_SAD     &rgb_ug RGB_HUD     &trans    
&none               &none               &none               &none               &none               &kp LG(UP)           &none                           &trans                       &trans                &trans              &trans              &trans              &trans              &bt BT_CLR   
                                                            &kp C_NEXT          &kp LG(SPACE)       &kp ENTER                                                                         &bl1                  &bl2                &bl3
            >;

            sensor-bindings = <&scroll_encoder>;
        };
// -------------------------------------------------------------------------------------------------------------------------------------------------------------------------------------------------------------------------------------------------------------------------------------------------------------------
        numbers {
            display-name = "Numbers";
            bindings = <
&buildl             &none               &kp KP_PLUS         &kp KP_MULTIPLY     &kp KP_DIVIDE       &kp MINUS                                         &trans                       &none               &kp KP_N7           &kp KP_N8           &kp KP_N9           &none               &kp KP_NLCK 
&none               &kp TAB             &kp KP_MINUS        &kp DOT             &kp SPACE           &kp LS(DOT)                       &buildr         &trans     &bootloader       &td1                &kp KP_N4           &kp KP_N5           &kp KP_N6           &none               &none
&none               &none               &none               &kp COMMA           &none               &none               &trans                        &trans                       &td0                &kp KP_N1           &kp KP_N2           &kp KP_N3           &none               &none 
                                                            &trans              &trans              &kp DOT                                                                        &kp BSPC            &kp KP_N0           &kp TAB     
            >;

            sensor-bindings = <&scroll_encoder>;
        };
// -------------------------------------------------------------------------------------------------------------------------------------------------------------------------------------------------------------------------------------------------------------------------------------------------------------------
        function {
            display-name = "Function";
            bindings = <
&trans              &kp F1              &kp F2              &kp F3              &kp F4              &kp F5                                            &trans                       &trans              &trans              &trans              &trans              &trans              &trans      
&trans              &trans              &kp F6              &kp F7              &kp F8              &kp F8                            &trans          &trans     &trans            &trans              &trans              &trans              &trans              &trans              &trans    
&trans              &trans              &kp F9              &kp F10             &kp F11             &kp F12              &trans                        &trans                       &trans              &trans              &trans              &trans              &trans              &trans    
                                                            &trans              &trans              &trans                                                                         &trans              &trans              &trans    
            >;

            sensor-bindings = <&scroll_encoder>;
        };
// -------------------------------------------------------------------------------------------------------------------------------------------------------------------------------------------------------------------------------------------------------------------------------------------------------------------
        empty_2 {
            display-name = "Empty";
            bindings = <
&trans              &trans              &trans              &trans              &trans              &trans                                            &trans                       &trans              &trans              &trans              &trans              &trans              &trans      
&trans              &trans              &trans              &trans              &trans              &trans                            &trans          &trans     &trans            &trans              &trans              &trans              &trans              &trans              &trans    
&trans              &trans              &trans              &trans              &trans              &trans              &trans                        &trans                       &trans              &trans              &trans              &trans              &trans              &trans    
                                                            &trans              &trans              &trans                                                                         &trans              &trans              &trans    
            >;

            sensor-bindings = <&scroll_encoder>;
        };
// -------------------------------------------------------------------------------------------------------------------------------------------------------------------------------------------------------------------------------------------------------------------------------------------------------------------
    };
};

// -------------------------------------------------------------------------------------------------------------------------------------------------------------------------------------------------------------------------------------------------------------------------------------------------------------------
// -------------------------------------------------------------------------------------------------------------------------------------------------------------------------------------------------------------------------------------------------------------------------------------------------------------------
//         layer_name {
//             display-name = "Empty";
//             bindings = <
// &trans              &trans              &trans              &trans              &trans              &trans                                            &trans                       &trans              &trans              &trans              &trans              &trans              &trans      
// &trans              &trans              &trans              &trans              &trans              &trans                            &trans          &trans     &trans            &trans              &trans              &trans              &trans              &trans              &trans    
// &trans              &trans              &trans              &trans              &trans              &trans              &trans                        &trans                       &trans              &trans              &trans              &trans              &trans              &trans    
//                                                             &trans              &trans              &trans                                                                         &trans              &trans              &trans    
//             >
// -------------------------------------------------------------------------------------------------------------------------------------------------------------------------------------------------------------------------------------------------------------------------------------------------------------------
// -------------------------------------------------------------------------------------------------------------------------------------------------------------------------------------------------------------------------------------------------------------------------------------------------------------------
